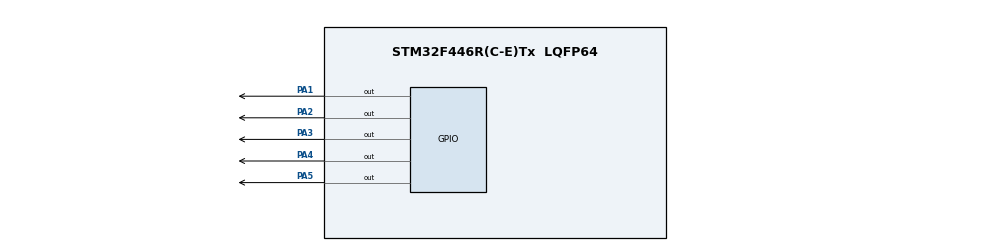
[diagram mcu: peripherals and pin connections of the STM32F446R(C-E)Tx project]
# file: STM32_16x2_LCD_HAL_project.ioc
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Mcu.Family=STM32F4
Mcu.Name=STM32F446R(C-E)Tx
Mcu.Package=LQFP64
NVIC.PriorityGroup=NVIC_PRIORITYGROUP_4
PA1.Signal=GPIO_Output
PA2.Signal=GPIO_Output
PA3.Signal=GPIO_Output
PA4.Signal=GPIO_Output
PA5.Signal=GPIO_Output
ProjectManager.HeapSize=0x200
ProjectManager.StackSize=0x400
ProjectManager.TargetToolchain=STM32CubeIDE
RCC.CortexFreq_Value=16000000
RCC.USBFreq_Value=96000000
RCC.VCOOutputFreq_Value=192000000
board=custom

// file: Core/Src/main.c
/* USER CODE BEGIN Header */
/**
  ******************************************************************************
  * @file           : main.c
  * @brief          : Main program body
  ******************************************************************************
  * @attention
  *
  * Copyright (c) 2025 STMicroelectronics.
  * All rights reserved.
  *
  * This software is licensed under terms that can be found in the LICENSE file
  * in the root directory of this software component.
  * If no LICENSE file comes with this software, it is provided AS-IS.
  *
  ******************************************************************************
  */
/* USER CODE END Header */
#include "main.h"
#include "gpio.h"

/* USER CODE BEGIN Includes */
#include "lcd.h"
/* USER CODE END Includes */

void SystemClock_Config(void);

int main(void)
{

  /* MCU Configuration--------------------------------------------------------*/

  /* Reset of all peripherals, Initializes the Flash interface and the Systick. */
  HAL_Init();

  /* Configure the system clock */
  SystemClock_Config();

  /* Initialize all configured peripherals */
  MX_GPIO_Init();
  /* USER CODE BEGIN 2 */
  LCD_Init();
  LCD_Set_Cursor(0,0);
  LCD_Send_String("STM32 HAL LCD");

  LCD_Set_Cursor(0,1);
  LCD_Send_String("Hello Daniel");
  /* USER CODE END 2 */

  /* Infinite loop */
  while (1)
  {

  }
}

void SystemClock_Config(void)
{
  RCC_OscInitTypeDef RCC_OscInitStruct = {0};
  RCC_ClkInitTypeDef RCC_ClkInitStruct = {0};

  /** Configure the main internal regulator output voltage
  */
  __HAL_RCC_PWR_CLK_ENABLE();
  __HAL_PWR_VOLTAGESCALING_CONFIG(PWR_REGULATOR_VOLTAGE_SCALE3);

  /** Initializes the RCC Oscillators according to the specified parameters
  * in the RCC_OscInitTypeDef structure.
  */
  RCC_OscInitStruct.OscillatorType = RCC_OSCILLATORTYPE_HSI;
  RCC_OscInitStruct.HSIState = RCC_HSI_ON;
  RCC_OscInitStruct.HSICalibrationValue = RCC_HSICALIBRATION_DEFAULT;
  RCC_OscInitStruct.PLL.PLLState = RCC_PLL_NONE;
  if (HAL_RCC_OscConfig(&RCC_OscInitStruct) != HAL_OK)
  {
    Error_Handler();
  }

  /** Initializes the CPU, AHB and APB buses clocks
  */
  RCC_ClkInitStruct.ClockType = RCC_CLOCKTYPE_HCLK|RCC_CLOCKTYPE_SYSCLK
                              |RCC_CLOCKTYPE_PCLK1|RCC_CLOCKTYPE_PCLK2;
  RCC_ClkInitStruct.SYSCLKSource = RCC_SYSCLKSOURCE_HSI;
  RCC_ClkInitStruct.AHBCLKDivider = RCC_SYSCLK_DIV1;
  RCC_ClkInitStruct.APB1CLKDivider = RCC_HCLK_DIV1;
  RCC_ClkInitStruct.APB2CLKDivider = RCC_HCLK_DIV1;

  if (HAL_RCC_ClockConfig(&RCC_ClkInitStruct, FLASH_LATENCY_0) != HAL_OK)
  {
    Error_Handler();
  }
}

void Error_Handler(void)
{
  __disable_irq();
  while (1)
  {
  }
}
